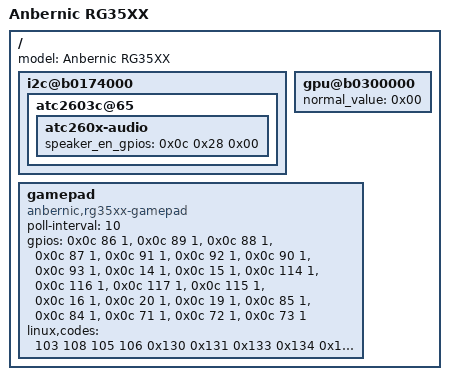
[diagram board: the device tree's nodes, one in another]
/*
 * Anbernic RG35XX (original), Onion kernel. Built as kernel.dtb (2600 mAh
 * battery); rg35xx-<capacity>.dts change only the battery table.
 */
/dts-v1/;

/include/ "gs705a.dtsi"

/ {
	model = "Anbernic RG35XX";

	i2c@b0174000 {
		atc2603c@65 {
			atc260x-audio {
				/* The speaker amplifier is enabled by a high level.
				 * The stock tree flags it active low, which the
				 * Garlic kernel ignores but this codec driver follows
				 * (the speaker stayed off) */
				speaker_en_gpios = <0x0c 0x28 0x00>;
			};
		};
	};

	/* PowerVR SGX544 (pvrsrvkm.ko). There is no GPU regulator: the driver
	 * falls back to dcdc1 (CPU) and only raises its minimum, at most to
	 * 1.2 V. normal_value 2 (stock) runs at 400 MHz; any other value at
	 * 300 MHz, used until the GPU is known to be stable */
	gpu@b0300000 {
		normal_value = <0x00>;
		status = "okay";
	};

	/* Codes from linux/input.h; START, SELECT, MENU and the volume keys
	 * have a second GPIO for another board revision */
	gamepad {
		compatible = "anbernic,rg35xx-gamepad";
		poll-interval = <10>;
		gpios = <0x0c 86 1>,	/* up */
			<0x0c 89 1>,	/* down */
			<0x0c 88 1>,	/* left */
			<0x0c 87 1>,	/* right */
			<0x0c 91 1>,	/* A */
			<0x0c 92 1>,	/* B */
			<0x0c 90 1>,	/* X */
			<0x0c 93 1>,	/* Y */
			<0x0c 14 1>,	/* START */
			<0x0c 15 1>,	/* SELECT */
			<0x0c 114 1>,	/* L1 */
			<0x0c 116 1>,	/* R1 */
			<0x0c 117 1>,	/* L2 */
			<0x0c 115 1>,	/* R2 */
			<0x0c 16 1>,	/* MENU */
			<0x0c 20 1>,	/* VOL+ */
			<0x0c 19 1>,	/* VOL- */
			<0x0c 85 1>,	/* START */
			<0x0c 84 1>,	/* SELECT */
			<0x0c 71 1>,	/* MENU */
			<0x0c 72 1>,	/* VOL+ */
			<0x0c 73 1>;	/* VOL- */
		linux,codes = <103 108 105 106	/* KEY_UP KEY_DOWN KEY_LEFT KEY_RIGHT */
			       0x130 0x131 0x133 0x134	/* BTN_A BTN_B BTN_X BTN_Y */
			       0x13b 0x13a		/* BTN_START BTN_SELECT */
			       0x136 0x137 0x138 0x139	/* BTN_TL BTN_TR BTN_TL2 BTN_TR2 */
			       0x13c 0x13d 0x13e	/* BTN_MODE BTN_THUMBL BTN_THUMBR */
			       0x13b 0x13a 0x13c 0x13d 0x13e>;
	};
};
